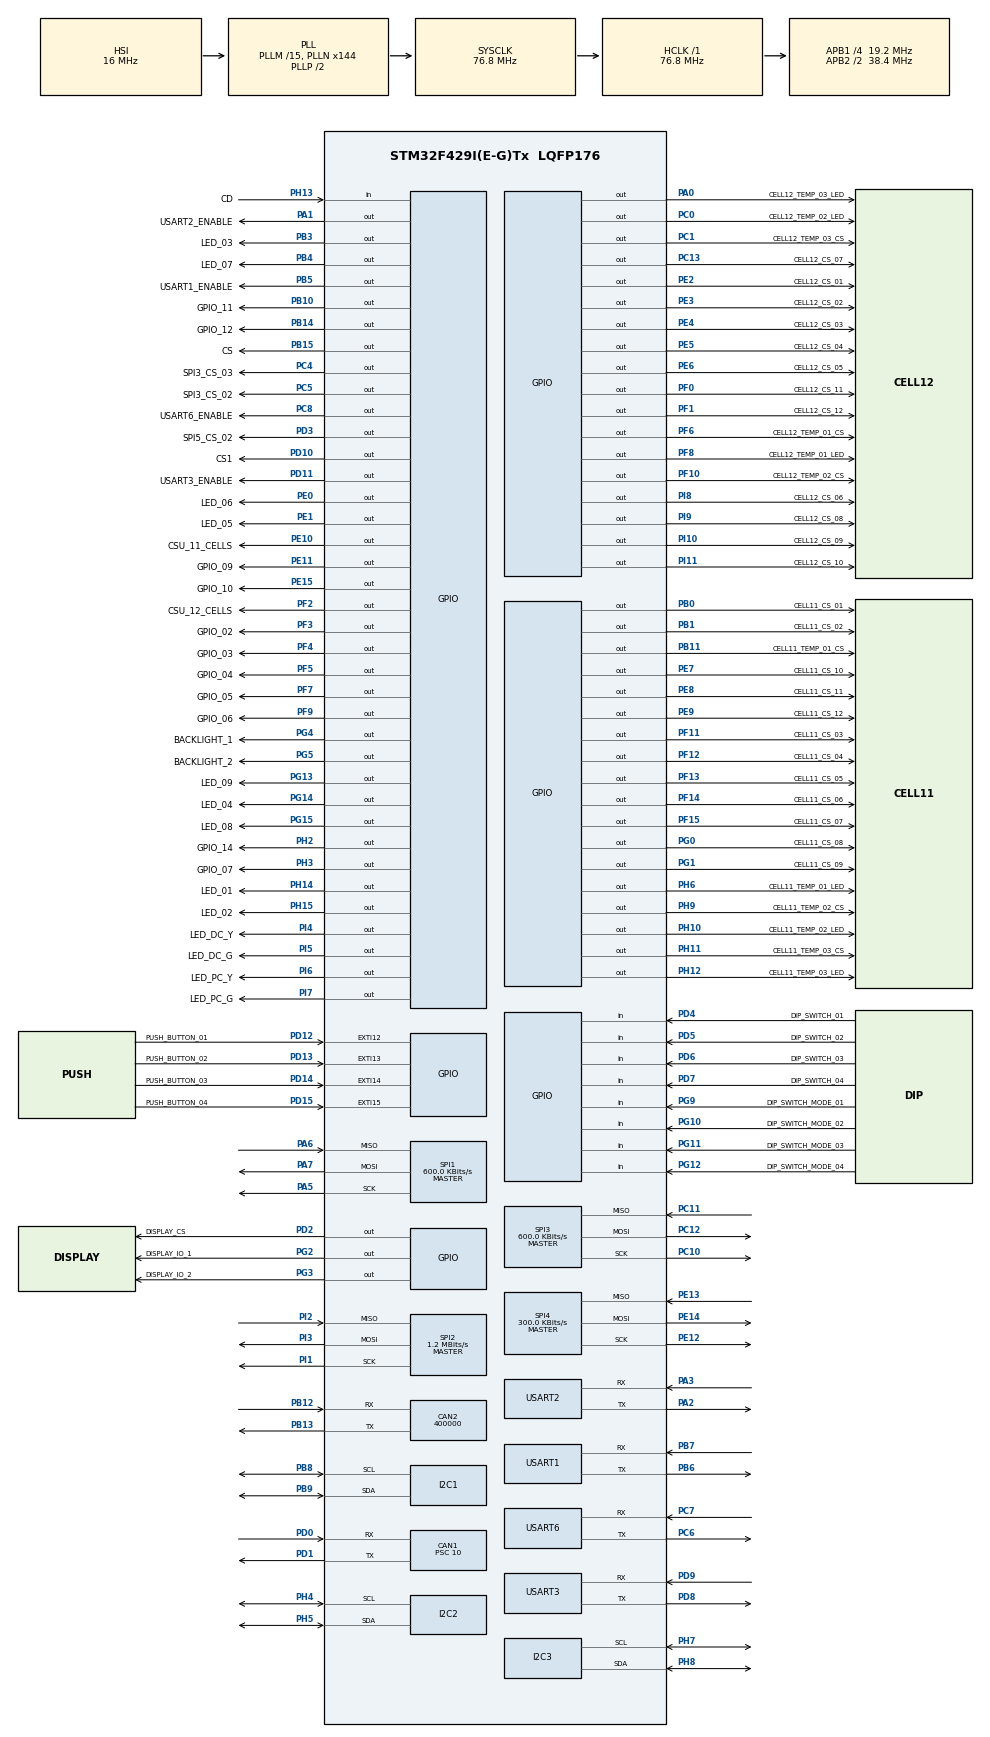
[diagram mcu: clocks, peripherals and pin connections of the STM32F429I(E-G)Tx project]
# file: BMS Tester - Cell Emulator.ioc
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CAN1.BS1=CAN_BS1_13TQ
CAN1.BS2=CAN_BS2_4TQ
CAN1.CalculateBaudRate=106666
CAN1.CalculateTimeBit=9375
CAN1.CalculateTimeQuantum=520.8333333333334
CAN1.Prescaler=10
CAN2.CalculateBaudRate=400000
CAN2.CalculateTimeBit=2500
CAN2.CalculateTimeQuantum=833.3333333333334
FATFS._MAX_SS=4096
I2C2.I2C_Mode=I2C_Fast
I2C3.I2C_Mode=I2C_Fast
Mcu.Family=STM32F4
Mcu.Name=STM32F429I(E-G)Tx
Mcu.Package=LQFP176
NVIC.CAN1_RX0_IRQn=true\:0\:0\:false\:false\:true\:true\:true\:true
NVIC.CAN1_RX1_IRQn=true\:0\:0\:false\:false\:true\:true\:true\:true
NVIC.EXTI15_10_IRQn=true\:0\:0\:false\:false\:true\:true\:true\:true
NVIC.PriorityGroup=NVIC_PRIORITYGROUP_4
NVIC.TIM1_UP_TIM10_IRQn=true\:0\:0\:false\:false\:true\:true\:true\:true
NVIC.USART1_IRQn=true\:0\:0\:false\:false\:true\:true\:true\:true
NVIC.USART2_IRQn=true\:0\:0\:false\:false\:true\:true\:true\:true
NVIC.USART3_IRQn=true\:0\:0\:false\:false\:true\:true\:true\:true
NVIC.USART6_IRQn=true\:0\:0\:false\:false\:true\:true\:true\:true
PA0/WKUP.GPIO_Label=CELL12_TEMP_03_LED
PA0/WKUP.GPIO_PuPd=GPIO_PULLDOWN
PA0/WKUP.GPIO_Speed=GPIO_SPEED_FREQ_VERY_HIGH
PA0/WKUP.PinState=GPIO_PIN_SET
PA0/WKUP.Signal=GPIO_Output
PA1.GPIO_Label=USART2_ENABLE
PA1.GPIO_Speed=GPIO_SPEED_FREQ_HIGH
PA1.PinState=GPIO_PIN_RESET
PA1.Signal=GPIO_Output
PA13.Mode=Serial_Wire
PA13.Signal=SYS_JTMS-SWDIO
PA14.Mode=Serial_Wire
PA14.Signal=SYS_JTCK-SWCLK
PA2.Mode=Asynchronous
PA2.Signal=USART2_TX
PA3.Mode=Asynchronous
PA3.Signal=USART2_RX
PA5.Mode=Full_Duplex_Master
PA5.Signal=SPI1_SCK
PA6.Mode=Full_Duplex_Master
PA6.Signal=SPI1_MISO
PA7.Mode=Full_Duplex_Master
PA7.Signal=SPI1_MOSI
PB0.GPIO_Label=CELL11_CS_01
PB0.PinState=GPIO_PIN_SET
PB0.Signal=GPIO_Output
PB1.GPIO_Label=CELL11_CS_02
PB1.PinState=GPIO_PIN_SET
PB1.Signal=GPIO_Output
PB10.GPIO_Label=GPIO_11
PB10.Signal=GPIO_Output
PB11.GPIO_Label=CELL11_TEMP_01_CS
PB11.GPIO_PuPd=GPIO_PULLUP
PB11.GPIO_Speed=GPIO_SPEED_FREQ_VERY_HIGH
PB11.PinState=GPIO_PIN_SET
PB11.Signal=GPIO_Output
PB12.Mode=CAN_Activate
PB12.Signal=CAN2_RX
PB13.Mode=CAN_Activate
PB13.Signal=CAN2_TX
PB14.GPIO_Label=GPIO_12
PB14.Signal=GPIO_Output
PB15.GPIO_Label=CS
PB15.PinState=GPIO_PIN_SET
PB15.Signal=GPIO_Output
PB3.GPIO_Label=LED_03
PB3.Signal=GPIO_Output
PB4.GPIO_Label=LED_07
PB4.Signal=GPIO_Output
PB5.GPIO_Label=USART1_ENABLE
PB5.Signal=GPIO_Output
PB6.Mode=Asynchronous
PB6.Signal=USART1_TX
PB7.Mode=Asynchronous
PB7.Signal=USART1_RX
PB8.Mode=I2C
PB8.Signal=I2C1_SCL
PB9.Mode=I2C
PB9.Signal=I2C1_SDA
PC0.GPIO_Label=CELL12_TEMP_02_LED
PC0.GPIO_PuPd=GPIO_PULLDOWN
PC0.GPIO_Speed=GPIO_SPEED_FREQ_VERY_HIGH
PC0.PinState=GPIO_PIN_SET
PC0.Signal=GPIO_Output
PC1.GPIO_Label=CELL12_TEMP_03_CS
PC1.GPIO_PuPd=GPIO_PULLUP
PC1.GPIO_Speed=GPIO_SPEED_FREQ_VERY_HIGH
PC1.PinState=GPIO_PIN_SET
PC1.Signal=GPIO_Output
PC10.Mode=Full_Duplex_Master
PC10.Signal=SPI3_SCK
PC11.Mode=Full_Duplex_Master
PC11.Signal=SPI3_MISO
PC12.Mode=Full_Duplex_Master
PC12.Signal=SPI3_MOSI
PC13.GPIO_Label=CELL12_CS_07
PC13.PinState=GPIO_PIN_SET
PC13.Signal=GPIO_Output
PC14/OSC32_IN.Mode=LSE-External-Oscillator
PC14/OSC32_IN.Signal=RCC_OSC32_IN
PC15/OSC32_OUT.Mode=LSE-External-Oscillator
PC15/OSC32_OUT.Signal=RCC_OSC32_OUT
PC4.GPIO_Label=SPI3_CS_03
PC4.PinState=GPIO_PIN_SET
PC4.Signal=GPIO_Output
PC5.GPIO_Label=SPI3_CS_02
PC5.PinState=GPIO_PIN_SET
PC5.Signal=GPIO_Output
PC6.Mode=Asynchronous
PC6.Signal=USART6_TX
PC7.Mode=Asynchronous
PC7.Signal=USART6_RX
PC8.GPIO_Label=USART6_ENABLE
PC8.Signal=GPIO_Output
PD0.Mode=CAN_Activate
PD0.Signal=CAN1_RX
PD1.Mode=CAN_Activate
PD1.Signal=CAN1_TX
PD10.GPIO_Label=CS1
PD10.PinState=GPIO_PIN_SET
PD10.Signal=GPIO_Output
PD11.GPIO_Label=USART3_ENABLE
PD11.Signal=GPIO_Output
PD12.GPIO_Label=PUSH_BUTTON_01
PD12.Signal=GPXTI12
PD13.GPIO_Label=PUSH_BUTTON_02
PD13.Signal=GPXTI13
PD14.GPIO_Label=PUSH_BUTTON_03
PD14.Signal=GPXTI14
PD15.GPIO_Label=PUSH_BUTTON_04
PD15.Signal=GPXTI15
PD2.GPIO_Label=DISPLAY_CS
PD2.Signal=GPIO_Output
PD3.GPIO_Label=SPI5_CS_02
PD3.Signal=GPIO_Output
PD4.GPIO_Label=DIP_SWITCH_01
PD4.Signal=GPIO_Input
PD5.GPIO_Label=DIP_SWITCH_02
PD5.Signal=GPIO_Input
PD6.GPIO_Label=DIP_SWITCH_03
PD6.Signal=GPIO_Input
PD7.GPIO_Label=DIP_SWITCH_04
PD7.Signal=GPIO_Input
PD8.Mode=Asynchronous
PD8.Signal=USART3_TX
PD9.Mode=Asynchronous
PD9.Signal=USART3_RX
PE0.GPIO_Label=LED_06
PE0.Signal=GPIO_Output
PE1.GPIO_Label=LED_05
PE1.Signal=GPIO_Output
PE10.GPIO_Label=CSU_11_CELLS
PE10.PinState=GPIO_PIN_SET
PE10.Signal=GPIO_Output
PE11.GPIO_Label=GPIO_09
PE11.Signal=GPIO_Output
PE12.Mode=Full_Duplex_Master
PE12.Signal=SPI4_SCK
PE13.GPIO_PuPd=GPIO_PULLUP
PE13.Mode=Full_Duplex_Master
PE13.Signal=SPI4_MISO
PE14.Mode=Full_Duplex_Master
PE14.Signal=SPI4_MOSI
PE15.GPIO_Label=GPIO_10
PE15.Signal=GPIO_Output
PE2.GPIO_Label=CELL12_CS_01
PE2.PinState=GPIO_PIN_SET
PE2.Signal=GPIO_Output
PE3.GPIO_Label=CELL12_CS_02
PE3.PinState=GPIO_PIN_SET
PE3.Signal=GPIO_Output
PE4.GPIO_Label=CELL12_CS_03
PE4.PinState=GPIO_PIN_SET
PE4.Signal=GPIO_Output
PE5.GPIO_Label=CELL12_CS_04
PE5.PinState=GPIO_PIN_SET
PE5.Signal=GPIO_Output
PE6.GPIO_Label=CELL12_CS_05
PE6.PinState=GPIO_PIN_SET
PE6.Signal=GPIO_Output
PE7.GPIO_Label=CELL11_CS_10
PE7.GPIO_PuPd=GPIO_NOPULL
PE7.PinState=GPIO_PIN_SET
PE7.Signal=GPIO_Output
PE8.GPIO_Label=CELL11_CS_11
PE8.PinState=GPIO_PIN_SET
PE8.Signal=GPIO_Output
PE9.GPIO_Label=CELL11_CS_12
PE9.PinState=GPIO_PIN_SET
PE9.Signal=GPIO_Output
PF0.GPIO_Label=CELL12_CS_11
PF0.PinState=GPIO_PIN_SET
PF0.Signal=GPIO_Output
PF1.GPIO_Label=CELL12_CS_12
PF1.PinState=GPIO_PIN_SET
PF1.Signal=GPIO_Output
PF10.GPIO_Label=CELL12_TEMP_02_CS
PF10.GPIO_PuPd=GPIO_PULLUP
PF10.GPIO_Speed=GPIO_SPEED_FREQ_VERY_HIGH
PF10.PinState=GPIO_PIN_SET
PF10.Signal=GPIO_Output
PF11.GPIO_Label=CELL11_CS_03
PF11.PinState=GPIO_PIN_SET
PF11.Signal=GPIO_Output
PF12.GPIO_Label=CELL11_CS_04
PF12.PinState=GPIO_PIN_SET
PF12.Signal=GPIO_Output
PF13.GPIO_Label=CELL11_CS_05
PF13.PinState=GPIO_PIN_SET
PF13.Signal=GPIO_Output
PF14.GPIO_Label=CELL11_CS_06
PF14.PinState=GPIO_PIN_SET
PF14.Signal=GPIO_Output
PF15.GPIO_Label=CELL11_CS_07
PF15.PinState=GPIO_PIN_SET
PF15.Signal=GPIO_Output
PF2.GPIO_Label=CSU_12_CELLS
PF2.GPIO_Speed=GPIO_SPEED_FREQ_HIGH
PF2.PinState=GPIO_PIN_SET
PF2.Signal=GPIO_Output
PF3.GPIO_Label=GPIO_02
PF3.Signal=GPIO_Output
PF4.GPIO_Label=GPIO_03
PF4.Signal=GPIO_Output
PF5.GPIO_Label=GPIO_04
PF5.Signal=GPIO_Output
PF6.GPIO_Label=CELL12_TEMP_01_CS
PF6.GPIO_PuPd=GPIO_PULLUP
PF6.GPIO_Speed=GPIO_SPEED_FREQ_VERY_HIGH
PF6.PinState=GPIO_PIN_SET
PF6.Signal=GPIO_Output
PF7.GPIO_Label=GPIO_05
PF7.Signal=GPIO_Output
PF8.GPIO_Label=CELL12_TEMP_01_LED
PF8.GPIO_PuPd=GPIO_PULLDOWN
PF8.GPIO_Speed=GPIO_SPEED_FREQ_VERY_HIGH
PF8.PinState=GPIO_PIN_SET
PF8.Signal=GPIO_Output
PF9.GPIO_Label=GPIO_06
PF9.Signal=GPIO_Output
PG0.GPIO_Label=CELL11_CS_08
PG0.PinState=GPIO_PIN_SET
PG0.Signal=GPIO_Output
PG1.GPIO_Label=CELL11_CS_09
PG1.GPIO_PuPd=GPIO_NOPULL
PG1.PinState=GPIO_PIN_SET
PG1.Signal=GPIO_Output
PG10.GPIO_Label=DIP_SWITCH_MODE_02
PG10.Signal=GPIO_Input
PG11.GPIO_Label=DIP_SWITCH_MODE_03
PG11.Signal=GPIO_Input
PG12.GPIO_Label=DIP_SWITCH_MODE_04
PG12.Signal=GPIO_Input
PG13.GPIO_Label=LED_09
PG13.Signal=GPIO_Output
PG14.GPIO_Label=LED_04
PG14.Signal=GPIO_Output
PG15.GPIO_Label=LED_08
PG15.Signal=GPIO_Output
PG2.GPIO_Label=DISPLAY_IO_1
PG2.Signal=GPIO_Output
PG3.GPIO_Label=DISPLAY_IO_2
PG3.Signal=GPIO_Output
PG4.GPIO_Label=BACKLIGHT_1
PG4.Signal=GPIO_Output
PG5.GPIO_Label=BACKLIGHT_2
PG5.Signal=GPIO_Output
PG9.GPIO_Label=DIP_SWITCH_MODE_01
PG9.Signal=GPIO_Input
PH0/OSC_IN.Mode=HSE-External-Oscillator
PH0/OSC_IN.Signal=RCC_OSC_IN
PH1/OSC_OUT.Mode=HSE-External-Oscillator
PH1/OSC_OUT.Signal=RCC_OSC_OUT
PH10.GPIO_Label=CELL11_TEMP_02_LED
PH10.GPIO_PuPd=GPIO_PULLDOWN
PH10.GPIO_Speed=GPIO_SPEED_FREQ_VERY_HIGH
PH10.PinState=GPIO_PIN_SET
PH10.Signal=GPIO_Output
PH11.GPIO_Label=CELL11_TEMP_03_CS
PH11.GPIO_PuPd=GPIO_PULLUP
PH11.GPIO_Speed=GPIO_SPEED_FREQ_VERY_HIGH
PH11.PinState=GPIO_PIN_SET
PH11.Signal=GPIO_Output
PH12.GPIO_Label=CELL11_TEMP_03_LED
PH12.GPIO_PuPd=GPIO_PULLDOWN
PH12.GPIO_Speed=GPIO_SPEED_FREQ_VERY_HIGH
PH12.PinState=GPIO_PIN_SET
PH12.Signal=GPIO_Output
PH13.GPIO_Label=CD
PH13.GPIO_PuPd=GPIO_PULLUP
PH13.Signal=GPIO_Input
PH14.GPIO_Label=LED_01
PH14.Signal=GPIO_Output
PH15.GPIO_Label=LED_02
PH15.Signal=GPIO_Output
PH2.GPIO_Label=GPIO_14
PH2.Signal=GPIO_Output
PH3.GPIO_Label=GPIO_07
PH3.Signal=GPIO_Output
PH4.Mode=I2C
PH4.Signal=I2C2_SCL
PH5.Mode=I2C
PH5.Signal=I2C2_SDA
PH6.GPIO_Label=CELL11_TEMP_01_LED
PH6.GPIO_PuPd=GPIO_PULLDOWN
PH6.GPIO_Speed=GPIO_SPEED_FREQ_VERY_HIGH
PH6.PinState=GPIO_PIN_SET
PH6.Signal=GPIO_Output
PH7.Mode=I2C
PH7.Signal=I2C3_SCL
PH8.Mode=I2C
PH8.Signal=I2C3_SDA
PH9.GPIO_Label=CELL11_TEMP_02_CS
PH9.GPIO_PuPd=GPIO_PULLUP
PH9.GPIO_Speed=GPIO_SPEED_FREQ_VERY_HIGH
PH9.PinState=GPIO_PIN_SET
PH9.Signal=GPIO_Output
PI1.Mode=Full_Duplex_Master
PI1.Signal=SPI2_SCK
PI10.GPIO_Label=CELL12_CS_09
PI10.PinState=GPIO_PIN_SET
PI10.Signal=GPIO_Output
PI11.GPIO_Label=CELL12_CS_10
PI11.PinState=GPIO_PIN_SET
PI11.Signal=GPIO_Output
PI2.Mode=Full_Duplex_Master
PI2.Signal=SPI2_MISO
PI3.Mode=Full_Duplex_Master
PI3.Signal=SPI2_MOSI
PI4.GPIO_Label=LED_DC_Y
PI4.Signal=GPIO_Output
PI5.GPIO_Label=LED_DC_G
PI5.Signal=GPIO_Output
PI6.GPIO_Label=LED_PC_Y
PI6.Signal=GPIO_Output
PI7.GPIO_Label=LED_PC_G
PI7.Signal=GPIO_Output
PI8.GPIO_Label=CELL12_CS_06
PI8.PinState=GPIO_PIN_SET
PI8.Signal=GPIO_Output
PI9.GPIO_Label=CELL12_CS_08
PI9.PinState=GPIO_PIN_SET
PI9.Signal=GPIO_Output
ProjectManager.HeapSize=0x200
ProjectManager.StackSize=0x400
ProjectManager.TargetToolchain=STM32CubeIDE
RCC.48MHZClocksFreq_Value=30720000
RCC.AHBFreq_Value=76800000
RCC.APB1CLKDivider=RCC_HCLK_DIV4
RCC.APB1Freq_Value=19200000
RCC.APB1TimFreq_Value=38400000
RCC.APB2CLKDivider=RCC_HCLK_DIV2
RCC.APB2Freq_Value=38400000
RCC.APB2TimFreq_Value=76800000
RCC.CortexFreq_Value=76800000
RCC.HCLKFreq_Value=76800000
RCC.HSE_VALUE=25000000
RCC.HSI_VALUE=16000000
RCC.PLLM=15
RCC.PLLN=144
RCC.PLLQ=5
RCC.SYSCLKFreq_VALUE=76800000
RCC.SYSCLKSource=RCC_SYSCLKSOURCE_PLLCLK
RCC.VCOOutputFreq_Value=153600000
SPI1.BaudRatePrescaler=SPI_BAUDRATEPRESCALER_64
SPI1.CLKPhase=SPI_PHASE_2EDGE
SPI1.CRCCalculation=SPI_CRCCALCULATION_DISABLE
SPI1.CalculateBaudRate=600.0 KBits/s
SPI1.Direction=SPI_DIRECTION_2LINES
SPI1.Mode=SPI_MODE_MASTER
SPI1.VirtualType=VM_MASTER
SPI2.BaudRatePrescaler=SPI_BAUDRATEPRESCALER_16
SPI2.CLKPhase=SPI_PHASE_2EDGE
SPI2.CalculateBaudRate=1.2 MBits/s
SPI2.Direction=SPI_DIRECTION_2LINES
SPI2.Mode=SPI_MODE_MASTER
SPI2.VirtualType=VM_MASTER
SPI3.BaudRatePrescaler=SPI_BAUDRATEPRESCALER_32
SPI3.CalculateBaudRate=600.0 KBits/s
SPI3.Direction=SPI_DIRECTION_2LINES
SPI3.Mode=SPI_MODE_MASTER
SPI3.VirtualType=VM_MASTER
SPI4.BaudRatePrescaler=SPI_BAUDRATEPRESCALER_128
SPI4.CalculateBaudRate=300.0 KBits/s
SPI4.Direction=SPI_DIRECTION_2LINES
SPI4.Mode=SPI_MODE_MASTER
SPI4.VirtualType=VM_MASTER
TIM1.Period=999
TIM1.Prescaler=999
USART1.VirtualMode=VM_ASYNC
USART2.VirtualMode=VM_ASYNC
USART3.VirtualMode=VM_ASYNC
USART6.VirtualMode=VM_ASYNC
VP_FATFS_VS_Generic.Mode=User_defined
VP_TIM1_VS_ClockSourceINT.Mode=Internal
board=custom

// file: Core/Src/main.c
/* USER CODE BEGIN Header */
/**
  ******************************************************************************
  * @file           : main.c
  * @brief          : Main program body
  ******************************************************************************
  * @attention
  *
  * Copyright (c) 2025 STMicroelectronics.
  * All rights reserved.
  *
  * This software is licensed under terms that can be found in the LICENSE file
  * in the root directory of this software component.
  * If no LICENSE file comes with this software, it is provided AS-IS.
  *
  ******************************************************************************
  */
/* USER CODE END Header */
#include "main.h"
#include "fatfs.h"

/* USER CODE BEGIN Includes */

#include "main_data.h"

#include "display.h"

#include "Temp_controller.h"

#include "INA229.h"
#include  "config.h"
#include "mcu.h"
#include <math.h>

#include "flash_LTC.h"
#include "LTC6811.h"
#include "LTC681x.h"
#include "LTC68xx_API.h"
#include <stdlib.h>

#include "gpio_expander.h"
#include "rtc.h"
#include "button_led.h"

#include "BMS_test_protocol.h"

#include "modbusSlave.h"

/* USER CODE END Includes */

/* USER CODE BEGIN PD */
int resistance[6] = {10, 10, 10, 10, 10, 10};

//uint8_t DC_chain = 0 ;

float set_temp = 1000.0 ;

uint8_t modebus_rx_flag = 0 ;
uint8_t flag_1 = 0 ;
uint8_t flag_2 = 0 ;
uint8_t flag_3 = 0 ;
uint8_t timeout_flag;
uint8_t testcount;

uint8_t RxData_modbus_01[256];
uint8_t TxData_modbus_01[256];

uint8_t RxData_modbus_02[256];
uint8_t TxData_modbus_02[256];

uint8_t RxData_modbus_03[256];
uint8_t TxData_modbus_03[256];

uint8_t RxData_modbus_04[256];
uint8_t TxData_modbus_04[256];

uint8_t address;
HAL_StatusTypeDef result;

int count =0 ;

#define STARTUP_TEMP_C 25.0f  // Desired startup temperature in °C

#define UI_BUFFER_SIZE 32
#define CRC16_CCITT 0x1021
#define debug
#define BAUD    115200
#define T_char  750
#define T_frame 1750

INA229_Handle ina229_devices[NUM_INA229];

/* USER CODE END PD */

CAN_HandleTypeDef hcan1;
CAN_HandleTypeDef hcan2;

I2C_HandleTypeDef hi2c1;
I2C_HandleTypeDef hi2c2;
I2C_HandleTypeDef hi2c3;

SPI_HandleTypeDef hspi1;
SPI_HandleTypeDef hspi2;
SPI_HandleTypeDef hspi3;
SPI_HandleTypeDef hspi4;

TIM_HandleTypeDef htim1;

UART_HandleTypeDef huart1;
UART_HandleTypeDef huart2;
UART_HandleTypeDef huart3;
UART_HandleTypeDef huart6;

void SystemClock_Config(void);
static void MX_GPIO_Init(void);
static void MX_SPI1_Init(void);
static void MX_SPI2_Init(void);
static void MX_I2C2_Init(void);
static void MX_I2C3_Init(void);
static void MX_SPI3_Init(void);
static void MX_SPI4_Init(void);
static void MX_CAN1_Init(void);
static void MX_CAN2_Init(void);
static void MX_I2C1_Init(void);
static void MX_USART1_UART_Init(void);
static void MX_USART2_UART_Init(void);
static void MX_USART3_UART_Init(void);
static void MX_USART6_UART_Init(void);
static void MX_TIM1_Init(void);
/* USER CODE BEGIN PFP */

//void Scan_I2C_Bus(void);

//// Define configuration structure using constant values
//typedef struct {
//    uint8_t cell_id;      // Cell ID as a number instead of enum
//    uint8_t ina_index;    // Index of INA229 (0-23)
//    GPIO_TypeDef* gpio;   // GPIO port (this is actually a constant address)
//    uint16_t cs_pin;      // Chip select pin
//    uint16_t led_pin;     // LED pin
//} Cell_Config;

// Function declarations

void Voltage_Sequence_Automatic(void);

void Set_voltage_and_measure(const Cell_Config* cell, float voltage);

void init_ina229_devices(void) ;

void HAL_UARTEx_RxEventCallback(UART_HandleTypeDef *huart, uint16_t Size);

void test_currecnt_senser();

/* USER CODE END PFP */

int main(void)
{

  /* USER CODE BEGIN 1 */
	timeout_flag = 0;
    memset(RxData_modbus_01, 0, sizeof(RxData_modbus_01));
    memset(TxData_modbus_01, 0, sizeof(TxData_modbus_01));

  /* USER CODE END 1 */

  /* MCU Configuration--------------------------------------------------------*/

  /* Reset of all peripherals, Initializes the Flash interface and the Systick. */
  HAL_Init();

  /* Configure the system clock */
  SystemClock_Config();

  /* Initialize all configured peripherals */
  MX_GPIO_Init();
  MX_SPI1_Init();
  MX_SPI2_Init();
  MX_I2C2_Init();
  MX_I2C3_Init();
  MX_SPI3_Init();
  MX_SPI4_Init();
  MX_CAN1_Init();
  MX_CAN2_Init();
  MX_I2C1_Init();
  MX_USART1_UART_Init();
  MX_USART2_UART_Init();
  MX_USART3_UART_Init();
  MX_USART6_UART_Init();
  MX_FATFS_Init();
  MX_TIM1_Init();
  /* USER CODE BEGIN 2 */

  RTC_Init();
  LED_Init();		/* Reset all LEDs */

  init_ina229_devices();

  for (int i = 0; i < NUM_INA229; i++)
  { INA229_config(ina229_devices[i]); HAL_Delay(10); }

  mcu_spiInit(0);
  HAL_Delay(10);

//

  //init ltc ics

  //--------------------------------------------------------------//

	LTC6811_init_cfg(TOTAL_IC, BMS_IC);
	uint8_t main_current_ic;
	for (main_current_ic = 0; main_current_ic < TOTAL_IC; main_current_ic++) {
		LTC6811_set_cfgr(main_current_ic, BMS_IC, REF_ON, ADCOPT, GPIOBITS_A,
				DCCBITS_A, DCTOBITS, UV, OV);
	}
	LTC6811_wrcfg(TOTAL_IC, BMS_IC);
	LTC6811_reset_crc_count(TOTAL_IC, BMS_IC);
	LTC6811_init_reg_limits(TOTAL_IC, BMS_IC);

  //--------------------------------------------------------------//

  /* Initialize the display module */
  Display_Init();

  /* Display the main title page */
  Display_MainTitlePage();

  /* Initialize the expander at address 0x20 by configuring all its pins as outputs */
  Expander_InitAllDevices(&hi2c2);
  Expander_InitAllDevices(&hi2c3);

	HAL_UARTEx_ReceiveToIdle_IT(&huart1, RxData_modbus_01, 256);

	HAL_UARTEx_ReceiveToIdle_IT(&huart2, RxData_modbus_02, 256);

	HAL_UARTEx_ReceiveToIdle_IT(&huart3, RxData_modbus_03, 256);

	HAL_UARTEx_ReceiveToIdle_IT(&huart6, RxData_modbus_04, 256);

	HAL_TIM_Base_Start_IT(&htim1);

	float startup_resistance = ntc_resistance(STARTUP_TEMP_C);

//fixing the startup resistance of temperature cards
#ifdef start_Resistance_fix
		  cell12_Temp_01_startup(startup_resistance);
		  cell12_Temp_02_startup(startup_resistance);
		  cell12_Temp_03_startup(startup_resistance);
		  cell11_Temp_01_startup(startup_resistance);
		  cell11_Temp_02_startup(startup_resistance);
		  cell11_Temp_03_startup(startup_resistance);

#endif

  /* USER CODE END 2 */

  /* Infinite loop */
  /* USER CODE BEGIN WHILE */
  while (1)
  {
//	  RTC_ReadTime();
//	  char timeStr[16];
//	  char dateStr[16];
//	  sprintf(timeStr, "%02d:%02d:%02d", time.hour, time.minute, time.second);
//	  sprintf(dateStr, "%02d/%02d/%02d", time.day, time.month, time.year);
//	  display_lcd(timeStr);
//	  HAL_Delay(100);
//	  LED_Set(7, 0);

    /* USER CODE END WHILE */

    /* USER CODE BEGIN 3 */

	  Display_HandleButtons();
	  Display_Update();

	  HAL_Delay(10);
	  tester_setup();

	  if (timeout_flag )

	  {
//		  memset(Rx_Data, 0, sizeof(Rx_Data));

//		  sprintf(Tx_Data, "F103 %d", indx++);
//		    send_Data (Tx_Data);
		    HAL_Delay(10);
//	        tester_setup();

	    	memset(RxData_modbus_01, 0, sizeof(RxData_modbus_01));
	    	memset(TxData_modbus_01, 0, sizeof(TxData_modbus_01));
		  modebus_rx_flag = 0 ;

		    flag_1 = 0 ;

			  HAL_TIM_Base_Stop_IT(&htim1);
			  timeout_flag = 0;

//		  HAL_TIM_Base_Stop_IT(&htim1);

	  }

//		  cell12_Temp_01_Set(resistance[0]);
//		  cell12_Temp_02_Set(resistance[1]);
//		  cell12_Temp_03_Set(resistance[2]);
//		  cell11_Temp_01_Set(resistance[3]);
//		  cell11_Temp_02_Set(resistance[4]);
//		  cell11_Temp_03_Set(resistance[5]);

//	  cell12_Temp_01_Set(set_temp);
//	  cell12_Temp_02_Set(set_temp);
//	  cell12_Temp_03_Set(set_temp);
//
//		  cell11_Temp_01_Set(set_temp);
//		  cell11_Temp_02_Set(set_temp);
//		  cell11_Temp_03_Set(set_temp);

	  ////////////////////////////////////////////////////////////

	        // Perform voltage sequence and measurements

//		  Set_Output_Voltage(CELL_1, 4.2f);
//
//		  HAL_Delay(1000);
//
//		  Set_Output_Voltage(CELL_1, 2.0f);
//
//		  HAL_Delay(1000);
//
//		  Set_Output_Voltage(CELL_15, 4.2f);
//
//		  HAL_Delay(1000);
//
//
//		  Set_Output_Voltage(CELL_15, 2.0f);
//
//		  HAL_Delay(1000);
//
//		  Set_Output_Voltage(CELL_24, 4.2f);
//
//		  HAL_Delay(1000);
//
//		  Set_Output_Voltage(CELL_24, 2.0f);

//	        Voltage_Sequence_Automatic();

//      	cell_voltage_read();

//      	temparature_data_read();

//	        tester_setup();

	        // Process battery tests
//	        for (int cell = CELL_1; cell <= CELL_24; cell++) {
//	        	Set_LED_status(cell, ON);
//	        }

//	        test_currecnt_senser();

//	        for (int cell = CELL_1; cell <= CELL_24; cell++) {
//	        	Set_LED_status(cell, OFF);
//	        }
//	        HAL_Delay(1000);
//
//	        for (int cell = CELL_1; cell <= CELL_24; cell++) {
//	        	Set_Output_Voltage(cell, 4.2);
//	        }
//
//
//	        HAL_Delay(1000);
//
//	        for (int cell = CELL_1; cell <= CELL_24; cell++) {
//	        	Set_Output_Voltage(cell, 2.0);
//	        }
//	        HAL_Delay(1000);
//
//	        for (int cell = CELL_1; cell <= CELL_24; cell++) {
//	        	Set_LED_status(cell, ON);
//	        }

//
//HAL_GPIO_WritePin(GPIOC, SPI3_CS_03_Pin|SPI3_CS_02_Pin, GPIO_PIN_RESET);
//
//
//cell_voltage_read();
//delay_time_us(500000);
//temparature_data_read();
//
//HAL_GPIO_WritePin(GPIOC, SPI3_CS_03_Pin|SPI3_CS_02_Pin, GPIO_PIN_SET);
//
//HAL_Delay(10);
//
//
//cell_voltage_read();
//delay_time_us(500000);
//temparature_data_read();

//delay_time_us(500000);
//--------------------------------------------------------------//

		  	/////////////////////////////////////////////////////////////
//Scan_I2C_Bus();

  }
  /* USER CODE END 3 */
}

void SystemClock_Config(void)
{
  RCC_OscInitTypeDef RCC_OscInitStruct = {0};
  RCC_ClkInitTypeDef RCC_ClkInitStruct = {0};

  /** Configure the main internal regulator output voltage
  */
  __HAL_RCC_PWR_CLK_ENABLE();
  __HAL_PWR_VOLTAGESCALING_CONFIG(PWR_REGULATOR_VOLTAGE_SCALE3);

  /** Initializes the RCC Oscillators according to the specified parameters
  * in the RCC_OscInitTypeDef structure.
  */
  RCC_OscInitStruct.OscillatorType = RCC_OSCILLATORTYPE_HSI;
  RCC_OscInitStruct.HSIState = RCC_HSI_ON;
  RCC_OscInitStruct.HSICalibrationValue = RCC_HSICALIBRATION_DEFAULT;
  RCC_OscInitStruct.PLL.PLLState = RCC_PLL_ON;
  RCC_OscInitStruct.PLL.PLLSource = RCC_PLLSOURCE_HSI;
  RCC_OscInitStruct.PLL.PLLM = 15;
  RCC_OscInitStruct.PLL.PLLN = 144;
  RCC_OscInitStruct.PLL.PLLP = RCC_PLLP_DIV2;
  RCC_OscInitStruct.PLL.PLLQ = 5;
  if (HAL_RCC_OscConfig(&RCC_OscInitStruct) != HAL_OK)
  {
    Error_Handler();
  }

  /** Initializes the CPU, AHB and APB buses clocks
  */
  RCC_ClkInitStruct.ClockType = RCC_CLOCKTYPE_HCLK|RCC_CLOCKTYPE_SYSCLK
                              |RCC_CLOCKTYPE_PCLK1|RCC_CLOCKTYPE_PCLK2;
  RCC_ClkInitStruct.SYSCLKSource = RCC_SYSCLKSOURCE_PLLCLK;
  RCC_ClkInitStruct.AHBCLKDivider = RCC_SYSCLK_DIV1;
  RCC_ClkInitStruct.APB1CLKDivider = RCC_HCLK_DIV4;
  RCC_ClkInitStruct.APB2CLKDivider = RCC_HCLK_DIV2;

  if (HAL_RCC_ClockConfig(&RCC_ClkInitStruct, FLASH_LATENCY_2) != HAL_OK)
  {
    Error_Handler();
  }
}

static void MX_CAN1_Init(void)
{

  hcan1.Instance = CAN1;
  hcan1.Init.Prescaler = 10;
  hcan1.Init.Mode = CAN_MODE_NORMAL;
  hcan1.Init.SyncJumpWidth = CAN_SJW_1TQ;
  hcan1.Init.TimeSeg1 = CAN_BS1_13TQ;
  hcan1.Init.TimeSeg2 = CAN_BS2_4TQ;
  hcan1.Init.TimeTriggeredMode = DISABLE;
  hcan1.Init.AutoBusOff = DISABLE;
  hcan1.Init.AutoWakeUp = DISABLE;
  hcan1.Init.AutoRetransmission = DISABLE;
  hcan1.Init.ReceiveFifoLocked = DISABLE;
  hcan1.Init.TransmitFifoPriority = DISABLE;
  if (HAL_CAN_Init(&hcan1) != HAL_OK)
  {
    Error_Handler();
  }

}

static void MX_CAN2_Init(void)
{

  hcan2.Instance = CAN2;
  hcan2.Init.Prescaler = 16;
  hcan2.Init.Mode = CAN_MODE_NORMAL;
  hcan2.Init.SyncJumpWidth = CAN_SJW_1TQ;
  hcan2.Init.TimeSeg1 = CAN_BS1_1TQ;
  hcan2.Init.TimeSeg2 = CAN_BS2_1TQ;
  hcan2.Init.TimeTriggeredMode = DISABLE;
  hcan2.Init.AutoBusOff = DISABLE;
  hcan2.Init.AutoWakeUp = DISABLE;
  hcan2.Init.AutoRetransmission = DISABLE;
  hcan2.Init.ReceiveFifoLocked = DISABLE;
  hcan2.Init.TransmitFifoPriority = DISABLE;
  if (HAL_CAN_Init(&hcan2) != HAL_OK)
  {
    Error_Handler();
  }

}

static void MX_I2C1_Init(void)
{

  hi2c1.Instance = I2C1;
  hi2c1.Init.ClockSpeed = 100000;
  hi2c1.Init.DutyCycle = I2C_DUTYCYCLE_2;
  hi2c1.Init.OwnAddress1 = 0;
  hi2c1.Init.AddressingMode = I2C_ADDRESSINGMODE_7BIT;
  hi2c1.Init.DualAddressMode = I2C_DUALADDRESS_DISABLE;
  hi2c1.Init.OwnAddress2 = 0;
  hi2c1.Init.GeneralCallMode = I2C_GENERALCALL_DISABLE;
  hi2c1.Init.NoStretchMode = I2C_NOSTRETCH_DISABLE;
  if (HAL_I2C_Init(&hi2c1) != HAL_OK)
  {
    Error_Handler();
  }

  /** Configure Analogue filter
  */
  if (HAL_I2CEx_ConfigAnalogFilter(&hi2c1, I2C_ANALOGFILTER_ENABLE) != HAL_OK)
  {
    Error_Handler();
  }

  /** Configure Digital filter
  */
  if (HAL_I2CEx_ConfigDigitalFilter(&hi2c1, 0) != HAL_OK)
  {
    Error_Handler();
  }

}

static void MX_I2C2_Init(void)
{

  hi2c2.Instance = I2C2;
  hi2c2.Init.ClockSpeed = 400000;
  hi2c2.Init.DutyCycle = I2C_DUTYCYCLE_2;
  hi2c2.Init.OwnAddress1 = 0;
  hi2c2.Init.AddressingMode = I2C_ADDRESSINGMODE_7BIT;
  hi2c2.Init.DualAddressMode = I2C_DUALADDRESS_DISABLE;
  hi2c2.Init.OwnAddress2 = 0;
  hi2c2.Init.GeneralCallMode = I2C_GENERALCALL_DISABLE;
  hi2c2.Init.NoStretchMode = I2C_NOSTRETCH_DISABLE;
  if (HAL_I2C_Init(&hi2c2) != HAL_OK)
  {
    Error_Handler();
  }

  /** Configure Analogue filter
  */
  if (HAL_I2CEx_ConfigAnalogFilter(&hi2c2, I2C_ANALOGFILTER_ENABLE) != HAL_OK)
  {
    Error_Handler();
  }

  /** Configure Digital filter
  */
  if (HAL_I2CEx_ConfigDigitalFilter(&hi2c2, 0) != HAL_OK)
  {
    Error_Handler();
  }

}

static void MX_I2C3_Init(void)
{

  hi2c3.Instance = I2C3;
  hi2c3.Init.ClockSpeed = 400000;
  hi2c3.Init.DutyCycle = I2C_DUTYCYCLE_2;
  hi2c3.Init.OwnAddress1 = 0;
  hi2c3.Init.AddressingMode = I2C_ADDRESSINGMODE_7BIT;
  hi2c3.Init.DualAddressMode = I2C_DUALADDRESS_DISABLE;
  hi2c3.Init.OwnAddress2 = 0;
  hi2c3.Init.GeneralCallMode = I2C_GENERALCALL_DISABLE;
  hi2c3.Init.NoStretchMode = I2C_NOSTRETCH_DISABLE;
  if (HAL_I2C_Init(&hi2c3) != HAL_OK)
  {
    Error_Handler();
  }

  /** Configure Analogue filter
  */
  if (HAL_I2CEx_ConfigAnalogFilter(&hi2c3, I2C_ANALOGFILTER_ENABLE) != HAL_OK)
  {
    Error_Handler();
  }

  /** Configure Digital filter
  */
  if (HAL_I2CEx_ConfigDigitalFilter(&hi2c3, 0) != HAL_OK)
  {
    Error_Handler();
  }

}

static void MX_SPI1_Init(void)
{

  /* SPI1 parameter configuration*/
  hspi1.Instance = SPI1;
  hspi1.Init.Mode = SPI_MODE_MASTER;
  hspi1.Init.Direction = SPI_DIRECTION_2LINES;
  hspi1.Init.DataSize = SPI_DATASIZE_8BIT;
  hspi1.Init.CLKPolarity = SPI_POLARITY_LOW;
  hspi1.Init.CLKPhase = SPI_PHASE_2EDGE;
  hspi1.Init.NSS = SPI_NSS_SOFT;
  hspi1.Init.BaudRatePrescaler = SPI_BAUDRATEPRESCALER_64;
  hspi1.Init.FirstBit = SPI_FIRSTBIT_MSB;
  hspi1.Init.TIMode = SPI_TIMODE_DISABLE;
  hspi1.Init.CRCCalculation = SPI_CRCCALCULATION_DISABLE;
  hspi1.Init.CRCPolynomial = 10;
  if (HAL_SPI_Init(&hspi1) != HAL_OK)
  {
    Error_Handler();
  }

}

static void MX_SPI2_Init(void)
{

  /* SPI2 parameter configuration*/
  hspi2.Instance = SPI2;
  hspi2.Init.Mode = SPI_MODE_MASTER;
  hspi2.Init.Direction = SPI_DIRECTION_2LINES;
  hspi2.Init.DataSize = SPI_DATASIZE_8BIT;
  hspi2.Init.CLKPolarity = SPI_POLARITY_LOW;
  hspi2.Init.CLKPhase = SPI_PHASE_2EDGE;
  hspi2.Init.NSS = SPI_NSS_SOFT;
  hspi2.Init.BaudRatePrescaler = SPI_BAUDRATEPRESCALER_16;
  hspi2.Init.FirstBit = SPI_FIRSTBIT_MSB;
  hspi2.Init.TIMode = SPI_TIMODE_DISABLE;
  hspi2.Init.CRCCalculation = SPI_CRCCALCULATION_DISABLE;
  hspi2.Init.CRCPolynomial = 10;
  if (HAL_SPI_Init(&hspi2) != HAL_OK)
  {
    Error_Handler();
  }

}

static void MX_SPI3_Init(void)
{

  /* SPI3 parameter configuration*/
  hspi3.Instance = SPI3;
  hspi3.Init.Mode = SPI_MODE_MASTER;
  hspi3.Init.Direction = SPI_DIRECTION_2LINES;
  hspi3.Init.DataSize = SPI_DATASIZE_8BIT;
  hspi3.Init.CLKPolarity = SPI_POLARITY_LOW;
  hspi3.Init.CLKPhase = SPI_PHASE_1EDGE;
  hspi3.Init.NSS = SPI_NSS_SOFT;
  hspi3.Init.BaudRatePrescaler = SPI_BAUDRATEPRESCALER_32;
  hspi3.Init.FirstBit = SPI_FIRSTBIT_MSB;
  hspi3.Init.TIMode = SPI_TIMODE_DISABLE;
  hspi3.Init.CRCCalculation = SPI_CRCCALCULATION_DISABLE;
  hspi3.Init.CRCPolynomial = 10;
  if (HAL_SPI_Init(&hspi3) != HAL_OK)
  {
    Error_Handler();
  }

}

static void MX_SPI4_Init(void)
{

  /* SPI4 parameter configuration*/
  hspi4.Instance = SPI4;
  hspi4.Init.Mode = SPI_MODE_MASTER;
  hspi4.Init.Direction = SPI_DIRECTION_2LINES;
  hspi4.Init.DataSize = SPI_DATASIZE_8BIT;
  hspi4.Init.CLKPolarity = SPI_POLARITY_LOW;
  hspi4.Init.CLKPhase = SPI_PHASE_1EDGE;
  hspi4.Init.NSS = SPI_NSS_SOFT;
  hspi4.Init.BaudRatePrescaler = SPI_BAUDRATEPRESCALER_128;
  hspi4.Init.FirstBit = SPI_FIRSTBIT_MSB;
  hspi4.Init.TIMode = SPI_TIMODE_DISABLE;
  hspi4.Init.CRCCalculation = SPI_CRCCALCULATION_DISABLE;
  hspi4.Init.CRCPolynomial = 10;
  if (HAL_SPI_Init(&hspi4) != HAL_OK)
  {
    Error_Handler();
  }

}

static void MX_TIM1_Init(void)
{

  TIM_ClockConfigTypeDef sClockSourceConfig = {0};
  TIM_MasterConfigTypeDef sMasterConfig = {0};

  htim1.Instance = TIM1;
  htim1.Init.Prescaler = 999;
  htim1.Init.CounterMode = TIM_COUNTERMODE_UP;
  htim1.Init.Period = 999;
  htim1.Init.ClockDivision = TIM_CLOCKDIVISION_DIV1;
  htim1.Init.RepetitionCounter = 0;
  htim1.Init.AutoReloadPreload = TIM_AUTORELOAD_PRELOAD_DISABLE;
  if (HAL_TIM_Base_Init(&htim1) != HAL_OK)
  {
    Error_Handler();
  }
  sClockSourceConfig.ClockSource = TIM_CLOCKSOURCE_INTERNAL;
  if (HAL_TIM_ConfigClockSource(&htim1, &sClockSourceConfig) != HAL_OK)
  {
    Error_Handler();
  }
  sMasterConfig.MasterOutputTrigger = TIM_TRGO_RESET;
  sMasterConfig.MasterSlaveMode = TIM_MASTERSLAVEMODE_DISABLE;
  if (HAL_TIMEx_MasterConfigSynchronization(&htim1, &sMasterConfig) != HAL_OK)
  {
    Error_Handler();
  }

}

static void MX_USART1_UART_Init(void)
{

  huart1.Instance = USART1;
  huart1.Init.BaudRate = 115200;
  huart1.Init.WordLength = UART_WORDLENGTH_8B;
  huart1.Init.StopBits = UART_STOPBITS_1;
  huart1.Init.Parity = UART_PARITY_NONE;
  huart1.Init.Mode = UART_MODE_TX_RX;
  huart1.Init.HwFlowCtl = UART_HWCONTROL_NONE;
  huart1.Init.OverSampling = UART_OVERSAMPLING_16;
  if (HAL_UART_Init(&huart1) != HAL_OK)
  {
    Error_Handler();
  }

}

static void MX_USART2_UART_Init(void)
{

  huart2.Instance = USART2;
  huart2.Init.BaudRate = 115200;
  huart2.Init.WordLength = UART_WORDLENGTH_8B;
  huart2.Init.StopBits = UART_STOPBITS_1;
  huart2.Init.Parity = UART_PARITY_NONE;
  huart2.Init.Mode = UART_MODE_TX_RX;
  huart2.Init.HwFlowCtl = UART_HWCONTROL_NONE;
  huart2.Init.OverSampling = UART_OVERSAMPLING_16;
  if (HAL_UART_Init(&huart2) != HAL_OK)
  {
    Error_Handler();
  }

}

static void MX_USART3_UART_Init(void)
{

  huart3.Instance = USART3;
  huart3.Init.BaudRate = 115200;
  huart3.Init.WordLength = UART_WORDLENGTH_8B;
  huart3.Init.StopBits = UART_STOPBITS_1;
  huart3.Init.Parity = UART_PARITY_NONE;
  huart3.Init.Mode = UART_MODE_TX_RX;
  huart3.Init.HwFlowCtl = UART_HWCONTROL_NONE;
  huart3.Init.OverSampling = UART_OVERSAMPLING_16;
  if (HAL_UART_Init(&huart3) != HAL_OK)
  {
    Error_Handler();
  }

}

static void MX_USART6_UART_Init(void)
{

  huart6.Instance = USART6;
  huart6.Init.BaudRate = 115200;
  huart6.Init.WordLength = UART_WORDLENGTH_8B;
  huart6.Init.StopBits = UART_STOPBITS_1;
  huart6.Init.Parity = UART_PARITY_NONE;
  huart6.Init.Mode = UART_MODE_TX_RX;
  huart6.Init.HwFlowCtl = UART_HWCONTROL_NONE;
  huart6.Init.OverSampling = UART_OVERSAMPLING_16;
  if (HAL_UART_Init(&huart6) != HAL_OK)
  {
    Error_Handler();
  }

}

static void MX_GPIO_Init(void)
{
  GPIO_InitTypeDef GPIO_InitStruct = {0};

  /* GPIO Ports Clock Enable */
  __HAL_RCC_GPIOE_CLK_ENABLE();
  __HAL_RCC_GPIOI_CLK_ENABLE();
  __HAL_RCC_GPIOC_CLK_ENABLE();
  __HAL_RCC_GPIOF_CLK_ENABLE();
  __HAL_RCC_GPIOH_CLK_ENABLE();
  __HAL_RCC_GPIOA_CLK_ENABLE();
  __HAL_RCC_GPIOB_CLK_ENABLE();
  __HAL_RCC_GPIOG_CLK_ENABLE();
  __HAL_RCC_GPIOD_CLK_ENABLE();

  /*Configure GPIO pin Output Level */
  HAL_GPIO_WritePin(GPIOE, CELL12_CS_01_Pin|CELL12_CS_02_Pin|CELL12_CS_03_Pin|CELL12_CS_04_Pin
                          |CELL12_CS_05_Pin|CELL11_CS_10_Pin|CELL11_CS_11_Pin|CELL11_CS_12_Pin
                          |CSU_11_CELLS_Pin, GPIO_PIN_SET);

  /*Configure GPIO pin Output Level */
  HAL_GPIO_WritePin(GPIOI, CELL12_CS_06_Pin|CELL12_CS_08_Pin|CELL12_CS_09_Pin|CELL12_CS_10_Pin, GPIO_PIN_SET);

  /*Configure GPIO pin Output Level */
  HAL_GPIO_WritePin(GPIOC, CELL12_CS_07_Pin|CELL12_TEMP_02_LED_Pin|CELL12_TEMP_03_CS_Pin|SPI3_CS_03_Pin
                          |SPI3_CS_02_Pin, GPIO_PIN_SET);

  /*Configure GPIO pin Output Level */
  HAL_GPIO_WritePin(GPIOF, CELL12_CS_11_Pin|CELL12_CS_12_Pin|CSU_12_CELLS_Pin|CELL12_TEMP_01_CS_Pin
                          |CELL12_TEMP_01_LED_Pin|CELL12_TEMP_02_CS_Pin|CELL11_CS_03_Pin|CELL11_CS_04_Pin
                          |CELL11_CS_05_Pin|CELL11_CS_06_Pin|CELL11_CS_07_Pin, GPIO_PIN_SET);

  /*Configure GPIO pin Output Level */
  HAL_GPIO_WritePin(GPIOF, GPIO_02_Pin|GPIO_03_Pin|GPIO_04_Pin|GPIO_05_Pin
                          |GPIO_06_Pin, GPIO_PIN_RESET);

  /*Configure GPIO pin Output Level */
  HAL_GPIO_WritePin(CELL12_TEMP_03_LED_GPIO_Port, CELL12_TEMP_03_LED_Pin, GPIO_PIN_SET);

  /*Configure GPIO pin Output Level */
  HAL_GPIO_WritePin(USART2_ENABLE_GPIO_Port, USART2_ENABLE_Pin, GPIO_PIN_RESET);

  /*Configure GPIO pin Output Level */
  HAL_GPIO_WritePin(GPIOH, GPIO_14_Pin|GPIO_07_Pin|LED_01_Pin|LED_02_Pin, GPIO_PIN_RESET);

  /*Configure GPIO pin Output Level */
  HAL_GPIO_WritePin(GPIOB, CELL11_CS_01_Pin|CELL11_CS_02_Pin|CELL11_TEMP_01_CS_Pin|CS_Pin, GPIO_PIN_SET);

  /*Configure GPIO pin Output Level */
  HAL_GPIO_WritePin(GPIOG, CELL11_CS_08_Pin|CELL11_CS_09_Pin, GPIO_PIN_SET);

  /*Configure GPIO pin Output Level */
  HAL_GPIO_WritePin(GPIOE, GPIO_09_Pin|GPIO_10_Pin|LED_06_Pin|LED_05_Pin, GPIO_PIN_RESET);

  /*Configure GPIO pin Output Level */
  HAL_GPIO_WritePin(GPIOB, GPIO_11_Pin|GPIO_12_Pin|LED_03_Pin|LED_07_Pin
                          |USART1_ENABLE_Pin, GPIO_PIN_RESET);

  /*Configure GPIO pin Output Level */
  HAL_GPIO_WritePin(GPIOH, CELL11_TEMP_01_LED_Pin|CELL11_TEMP_02_CS_Pin|CELL11_TEMP_02_LED_Pin|CELL11_TEMP_03_CS_Pin
                          |CELL11_TEMP_03_LED_Pin, GPIO_PIN_SET);

  /*Configure GPIO pin Output Level */
  HAL_GPIO_WritePin(CS1_GPIO_Port, CS1_Pin, GPIO_PIN_SET);

  /*Configure GPIO pin Output Level */
  HAL_GPIO_WritePin(GPIOD, USART3_ENABLE_Pin|DISPLAY_CS_Pin|SPI5_CS_02_Pin, GPIO_PIN_RESET);

  /*Configure GPIO pin Output Level */
  HAL_GPIO_WritePin(GPIOG, DISPLAY_IO_1_Pin|DISPLAY_IO_2_Pin|BACKLIGHT_1_Pin|BACKLIGHT_2_Pin
                          |LED_09_Pin|LED_04_Pin|LED_08_Pin, GPIO_PIN_RESET);

  /*Configure GPIO pin Output Level */
  HAL_GPIO_WritePin(USART6_ENABLE_GPIO_Port, USART6_ENABLE_Pin, GPIO_PIN_RESET);

  /*Configure GPIO pin Output Level */
  HAL_GPIO_WritePin(GPIOI, LED_DC_Y_Pin|LED_DC_G_Pin|LED_PC_Y_Pin|LED_PC_G_Pin, GPIO_PIN_RESET);

  /*Configure GPIO pins : CELL12_CS_01_Pin CELL12_CS_02_Pin CELL12_CS_03_Pin CELL12_CS_04_Pin
                           CELL12_CS_05_Pin CELL11_CS_10_Pin CELL11_CS_11_Pin CELL11_CS_12_Pin
                           CSU_11_CELLS_Pin GPIO_09_Pin GPIO_10_Pin LED_06_Pin
                           LED_05_Pin */
  GPIO_InitStruct.Pin = CELL12_CS_01_Pin|CELL12_CS_02_Pin|CELL12_CS_03_Pin|CELL12_CS_04_Pin
                          |CELL12_CS_05_Pin|CELL11_CS_10_Pin|CELL11_CS_11_Pin|CELL11_CS_12_Pin
                          |CSU_11_CELLS_Pin|GPIO_09_Pin|GPIO_10_Pin|LED_06_Pin
                          |LED_05_Pin;
  GPIO_InitStruct.Mode = GPIO_MODE_OUTPUT_PP;
  GPIO_InitStruct.Pull = GPIO_NOPULL;
  GPIO_InitStruct.Speed = GPIO_SPEED_FREQ_LOW;
  HAL_GPIO_Init(GPIOE, &GPIO_InitStruct);

  /*Configure GPIO pins : CELL12_CS_06_Pin CELL12_CS_08_Pin CELL12_CS_09_Pin CELL12_CS_10_Pin
                           LED_DC_Y_Pin LED_DC_G_Pin LED_PC_Y_Pin LED_PC_G_Pin */
  GPIO_InitStruct.Pin = CELL12_CS_06_Pin|CELL12_CS_08_Pin|CELL12_CS_09_Pin|CELL12_CS_10_Pin
                          |LED_DC_Y_Pin|LED_DC_G_Pin|LED_PC_Y_Pin|LED_PC_G_Pin;
  GPIO_InitStruct.Mode = GPIO_MODE_OUTPUT_PP;
  GPIO_InitStruct.Pull = GPIO_NOPULL;
  GPIO_InitStruct.Speed = GPIO_SPEED_FREQ_LOW;
  HAL_GPIO_Init(GPIOI, &GPIO_InitStruct);

  /*Configure GPIO pins : CELL12_CS_07_Pin SPI3_CS_03_Pin SPI3_CS_02_Pin USART6_ENABLE_Pin */
  GPIO_InitStruct.Pin = CELL12_CS_07_Pin|SPI3_CS_03_Pin|SPI3_CS_02_Pin|USART6_ENABLE_Pin;
  GPIO_InitStruct.Mode = GPIO_MODE_OUTPUT_PP;
  GPIO_InitStruct.Pull = GPIO_NOPULL;
  GPIO_InitStruct.Speed = GPIO_SPEED_FREQ_LOW;
  HAL_GPIO_Init(GPIOC, &GPIO_InitStruct);

  /*Configure GPIO pins : CELL12_CS_11_Pin CELL12_CS_12_Pin GPIO_02_Pin GPIO_03_Pin
                           GPIO_04_Pin GPIO_05_Pin GPIO_06_Pin CELL11_CS_03_Pin
                           CELL11_CS_04_Pin CELL11_CS_05_Pin CELL11_CS_06_Pin CELL11_CS_07_Pin */
  GPIO_InitStruct.Pin = CELL12_CS_11_Pin|CELL12_CS_12_Pin|GPIO_02_Pin|GPIO_03_Pin
                          |GPIO_04_Pin|GPIO_05_Pin|GPIO_06_Pin|CELL11_CS_03_Pin
                          |CELL11_CS_04_Pin|CELL11_CS_05_Pin|CELL11_CS_06_Pin|CELL11_CS_07_Pin;
  GPIO_InitStruct.Mode = GPIO_MODE_OUTPUT_PP;
  GPIO_InitStruct.Pull = GPIO_NOPULL;
  GPIO_InitStruct.Speed = GPIO_SPEED_FREQ_LOW;
  HAL_GPIO_Init(GPIOF, &GPIO_InitStruct);

  /*Configure GPIO pin : CSU_12_CELLS_Pin */
  GPIO_InitStruct.Pin = CSU_12_CELLS_Pin;
  GPIO_InitStruct.Mode = GPIO_MODE_OUTPUT_PP;
  GPIO_InitStruct.Pull = GPIO_NOPULL;
  GPIO_InitStruct.Speed = GPIO_SPEED_FREQ_HIGH;
  HAL_GPIO_Init(CSU_12_CELLS_GPIO_Port, &GPIO_InitStruct);

  /*Configure GPIO pins : CELL12_TEMP_01_CS_Pin CELL12_TEMP_02_CS_Pin */
  GPIO_InitStruct.Pin = CELL12_TEMP_01_CS_Pin|CELL12_TEMP_02_CS_Pin;
  GPIO_InitStruct.Mode = GPIO_MODE_OUTPUT_PP;
  GPIO_InitStruct.Pull = GPIO_PULLUP;
  GPIO_InitStruct.Speed = GPIO_SPEED_FREQ_VERY_HIGH;
  HAL_GPIO_Init(GPIOF, &GPIO_InitStruct);

  /*Configure GPIO pin : CELL12_TEMP_01_LED_Pin */
  GPIO_InitStruct.Pin = CELL12_TEMP_01_LED_Pin;
  GPIO_InitStruct.Mode = GPIO_MODE_OUTPUT_PP;
  GPIO_InitStruct.Pull = GPIO_PULLDOWN;
  GPIO_InitStruct.Speed = GPIO_SPEED_FREQ_VERY_HIGH;
  HAL_GPIO_Init(CELL12_TEMP_01_LED_GPIO_Port, &GPIO_InitStruct);

  /*Configure GPIO pin : CELL12_TEMP_02_LED_Pin */
  GPIO_InitStruct.Pin = CELL12_TEMP_02_LED_Pin;
  GPIO_InitStruct.Mode = GPIO_MODE_OUTPUT_PP;
  GPIO_InitStruct.Pull = GPIO_PULLDOWN;
  GPIO_InitStruct.Speed = GPIO_SPEED_FREQ_VERY_HIGH;
  HAL_GPIO_Init(CELL12_TEMP_02_LED_GPIO_Port, &GPIO_InitStruct);

  /*Configure GPIO pin : CELL12_TEMP_03_CS_Pin */
  GPIO_InitStruct.Pin = CELL12_TEMP_03_CS_Pin;
  GPIO_InitStruct.Mode = GPIO_MODE_OUTPUT_PP;
  GPIO_InitStruct.Pull = GPIO_PULLUP;
  GPIO_InitStruct.Speed = GPIO_SPEED_FREQ_VERY_HIGH;
  HAL_GPIO_Init(CELL12_TEMP_03_CS_GPIO_Port, &GPIO_InitStruct);

  /*Configure GPIO pin : CELL12_TEMP_03_LED_Pin */
  GPIO_InitStruct.Pin = CELL12_TEMP_03_LED_Pin;
  GPIO_InitStruct.Mode = GPIO_MODE_OUTPUT_PP;
  GPIO_InitStruct.Pull = GPIO_PULLDOWN;
  GPIO_InitStruct.Speed = GPIO_SPEED_FREQ_VERY_HIGH;
  HAL_GPIO_Init(CELL12_TEMP_03_LED_GPIO_Port, &GPIO_InitStruct);

  /*Configure GPIO pin : USART2_ENABLE_Pin */
  GPIO_InitStruct.Pin = USART2_ENABLE_Pin;
  GPIO_InitStruct.Mode = GPIO_MODE_OUTPUT_PP;
  GPIO_InitStruct.Pull = GPIO_NOPULL;
  GPIO_InitStruct.Speed = GPIO_SPEED_FREQ_HIGH;
  HAL_GPIO_Init(USART2_ENABLE_GPIO_Port, &GPIO_InitStruct);

  /*Configure GPIO pins : GPIO_14_Pin GPIO_07_Pin LED_01_Pin LED_02_Pin */
  GPIO_InitStruct.Pin = GPIO_14_Pin|GPIO_07_Pin|LED_01_Pin|LED_02_Pin;
  GPIO_InitStruct.Mode = GPIO_MODE_OUTPUT_PP;
  GPIO_InitStruct.Pull = GPIO_NOPULL;
  GPIO_InitStruct.Speed = GPIO_SPEED_FREQ_LOW;
  HAL_GPIO_Init(GPIOH, &GPIO_InitStruct);

  /*Configure GPIO pins : CELL11_CS_01_Pin CELL11_CS_02_Pin GPIO_11_Pin GPIO_12_Pin
                           CS_Pin LED_03_Pin LED_07_Pin USART1_ENABLE_Pin */
  GPIO_InitStruct.Pin = CELL11_CS_01_Pin|CELL11_CS_02_Pin|GPIO_11_Pin|GPIO_12_Pin
                          |CS_Pin|LED_03_Pin|LED_07_Pin|USART1_ENABLE_Pin;
  GPIO_InitStruct.Mode = GPIO_MODE_OUTPUT_PP;
  GPIO_InitStruct.Pull = GPIO_NOPULL;
  GPIO_InitStruct.Speed = GPIO_SPEED_FREQ_LOW;
  HAL_GPIO_Init(GPIOB, &GPIO_InitStruct);

  /*Configure GPIO pins : CELL11_CS_08_Pin CELL11_CS_09_Pin DISPLAY_IO_1_Pin DISPLAY_IO_2_Pin
                           BACKLIGHT_1_Pin BACKLIGHT_2_Pin LED_09_Pin LED_04_Pin
                           LED_08_Pin */
  GPIO_InitStruct.Pin = CELL11_CS_08_Pin|CELL11_CS_09_Pin|DISPLAY_IO_1_Pin|DISPLAY_IO_2_Pin
                          |BACKLIGHT_1_Pin|BACKLIGHT_2_Pin|LED_09_Pin|LED_04_Pin
                          |LED_08_Pin;
  GPIO_InitStruct.Mode = GPIO_MODE_OUTPUT_PP;
  GPIO_InitStruct.Pull = GPIO_NOPULL;
  GPIO_InitStruct.Speed = GPIO_SPEED_FREQ_LOW;
  HAL_GPIO_Init(GPIOG, &GPIO_InitStruct);

  /*Configure GPIO pin : CELL11_TEMP_01_CS_Pin */
  GPIO_InitStruct.Pin = CELL11_TEMP_01_CS_Pin;
  GPIO_InitStruct.Mode = GPIO_MODE_OUTPUT_PP;
  GPIO_InitStruct.Pull = GPIO_PULLUP;
  GPIO_InitStruct.Speed = GPIO_SPEED_FREQ_VERY_HIGH;
  HAL_GPIO_Init(CELL11_TEMP_01_CS_GPIO_Port, &GPIO_InitStruct);

  /*Configure GPIO pins : CELL11_TEMP_01_LED_Pin CELL11_TEMP_02_LED_Pin CELL11_TEMP_03_LED_Pin */
  GPIO_InitStruct.Pin = CELL11_TEMP_01_LED_Pin|CELL11_TEMP_02_LED_Pin|CELL11_TEMP_03_LED_Pin;
  GPIO_InitStruct.Mode = GPIO_MODE_OUTPUT_PP;
  GPIO_InitStruct.Pull = GPIO_PULLDOWN;
  GPIO_InitStruct.Speed = GPIO_SPEED_FREQ_VERY_HIGH;
  HAL_GPIO_Init(GPIOH, &GPIO_InitStruct);

  /*Configure GPIO pins : CELL11_TEMP_02_CS_Pin CELL11_TEMP_03_CS_Pin */
  GPIO_InitStruct.Pin = CELL11_TEMP_02_CS_Pin|CELL11_TEMP_03_CS_Pin;
  GPIO_InitStruct.Mode = GPIO_MODE_OUTPUT_PP;
  GPIO_InitStruct.Pull = GPIO_PULLUP;
  GPIO_InitStruct.Speed = GPIO_SPEED_FREQ_VERY_HIGH;
  HAL_GPIO_Init(GPIOH, &GPIO_InitStruct);

  /*Configure GPIO pins : CS1_Pin USART3_ENABLE_Pin DISPLAY_CS_Pin SPI5_CS_02_Pin */
  GPIO_InitStruct.Pin = CS1_Pin|USART3_ENABLE_Pin|DISPLAY_CS_Pin|SPI5_CS_02_Pin;
  GPIO_InitStruct.Mode = GPIO_MODE_OUTPUT_PP;
  GPIO_InitStruct.Pull = GPIO_NOPULL;
  GPIO_InitStruct.Speed = GPIO_SPEED_FREQ_LOW;
  HAL_GPIO_Init(GPIOD, &GPIO_InitStruct);

  /*Configure GPIO pins : PUSH_BUTTON_01_Pin PUSH_BUTTON_02_Pin PUSH_BUTTON_03_Pin PUSH_BUTTON_04_Pin */
  GPIO_InitStruct.Pin = PUSH_BUTTON_01_Pin|PUSH_BUTTON_02_Pin|PUSH_BUTTON_03_Pin|PUSH_BUTTON_04_Pin;
  GPIO_InitStruct.Mode = GPIO_MODE_IT_RISING;
  GPIO_InitStruct.Pull = GPIO_NOPULL;
  HAL_GPIO_Init(GPIOD, &GPIO_InitStruct);

  /*Configure GPIO pin : CD_Pin */
  GPIO_InitStruct.Pin = CD_Pin;
  GPIO_InitStruct.Mode = GPIO_MODE_INPUT;
  GPIO_InitStruct.Pull = GPIO_PULLUP;
  HAL_GPIO_Init(CD_GPIO_Port, &GPIO_InitStruct);

  /*Configure GPIO pins : DIP_SWITCH_01_Pin DIP_SWITCH_02_Pin DIP_SWITCH_03_Pin DIP_SWITCH_04_Pin */
  GPIO_InitStruct.Pin = DIP_SWITCH_01_Pin|DIP_SWITCH_02_Pin|DIP_SWITCH_03_Pin|DIP_SWITCH_04_Pin;
  GPIO_InitStruct.Mode = GPIO_MODE_INPUT;
  GPIO_InitStruct.Pull = GPIO_NOPULL;
  HAL_GPIO_Init(GPIOD, &GPIO_InitStruct);

  /*Configure GPIO pins : DIP_SWITCH_MODE_01_Pin DIP_SWITCH_MODE_02_Pin DIP_SWITCH_MODE_03_Pin DIP_SWITCH_MODE_04_Pin */
  GPIO_InitStruct.Pin = DIP_SWITCH_MODE_01_Pin|DIP_SWITCH_MODE_02_Pin|DIP_SWITCH_MODE_03_Pin|DIP_SWITCH_MODE_04_Pin;
  GPIO_InitStruct.Mode = GPIO_MODE_INPUT;
  GPIO_InitStruct.Pull = GPIO_NOPULL;
  HAL_GPIO_Init(GPIOG, &GPIO_InitStruct);

  /* EXTI interrupt init*/
  HAL_NVIC_SetPriority(EXTI15_10_IRQn, 0, 0);
  HAL_NVIC_EnableIRQ(EXTI15_10_IRQn);

}

/* USER CODE BEGIN 4 */

//void init_ina229_devices(void) {
//    ina229_devices[0] = INA229_0;
//    ina229_devices[1] = INA229_1;
//    ina229_devices[2] = INA229_2;
//    ina229_devices[3] = INA229_3;
//    ina229_devices[4] = INA229_4;
//    ina229_devices[5] = INA229_5;
//    ina229_devices[6] = INA229_6;
//    ina229_devices[7] = INA229_7;
//    ina229_devices[8] = INA229_8;
//    ina229_devices[9] = INA229_9;
//    ina229_devices[10] = INA229_10;
//    ina229_devices[11] = INA229_11;
//    ina229_devices[12] = INA229_12;
//    ina229_devices[13] = INA229_13;
//    ina229_devices[14] = INA229_14;
//    ina229_devices[15] = INA229_15;
//    ina229_devices[16] = INA229_16;
//    ina229_devices[17] = INA229_17;
//    ina229_devices[18] = INA229_18;
//    ina229_devices[19] = INA229_19;
//    ina229_devices[20] = INA229_20;
//    ina229_devices[21] = INA229_21;
//    ina229_devices[22] = INA229_22;
//    ina229_devices[23] = INA229_23;
//    ina229_devices[24] = INA229_24;
//    ina229_devices[25] = INA229_25;
//}

void Scan_I2C_Bus(void)
{

      /* Declare the address variable */

    /* Iterate over the possible 7-bit I²C addresses (1 to 127) */
    for (address = 1U; address < 128U; address++)
    {
        /* Check if a device is ready at this address
         * The address is left-shifted by 1 as HAL_I2C_IsDeviceReady expects the 7-bit address in the upper bits.
         */
        result = HAL_I2C_IsDeviceReady(&hi2c2, (address << 1), 1U, 10U);

        if (result == HAL_OK)
        {
            /* Display the detected address (your Display_Address function should handle this)
             * For example, this could light up LEDs or update an LCD.
             */
            Display_Address(address);
            HAL_Delay(1000U);  /* Display the address for 1 second */
        }
    }
}

// Helper macros to make the table more readable
#define I2C2_BUS 2
#define I2C3_BUS 3

//// Define the configurations table
//static const Cell_Config cell_configs[] = {
//		// First GPIO Expander (ID_01) - Cells 1-3
//
//		// FOR THE FIRST 12 CELLS
//    // Cell ID, INA idx, GPIO port,  CS pin,           LED pin
//    { 0,          0,       GPIOE,     CELL12_CS_01_Pin, CELL_01_LED_01},
//    { 1,          1,       GPIOE,     CELL12_CS_02_Pin, CELL_02_LED_01},
//    { 2,          2,       GPIOE,     CELL12_CS_03_Pin, CELL_03_LED_01},
//
//	// Second GPIO Expander (ID_02) - Cells 4-6
//    { 3,          3,       GPIOE,     CELL12_CS_04_Pin, CELL_01_LED_01},
//    { 4,          4,       GPIOE,     CELL12_CS_05_Pin, CELL_02_LED_01},
//    { 5,          5,       GPIOI,     CELL12_CS_06_Pin, CELL_03_LED_01},
//	// Third GPIO Expander (ID_03) - Cells 7-9
//    { 6,          6,       GPIOC,     CELL12_CS_07_Pin, CELL_01_LED_01},
//    { 7,          7,       GPIOI,     CELL12_CS_08_Pin, CELL_02_LED_01},
//    { 8,          8,       GPIOI,     CELL12_CS_09_Pin, CELL_03_LED_01},
//
//	// Fourth GPIO Expander (ID_04) - Cells 10-12
//    { 9,          9,       GPIOI,     CELL12_CS_10_Pin, CELL_01_LED_01},
//    {10,         10,       GPIOF,     CELL12_CS_11_Pin, CELL_02_LED_01},
//    {11,         11,       GPIOF,     CELL12_CS_12_Pin, CELL_03_LED_01},
//
//	// FOR THE SECOND 12 CELLS
//    // Cell ID, I2C bus, INA idx, GPIO port,  CS pin,           LED pin
//    {12,         13,       GPIOB,     CELL11_CS_01_Pin, CELL_01_LED_01},
//    {13,         14,       GPIOB,     CELL11_CS_02_Pin, CELL_02_LED_01},
//    {14,         15,       GPIOF,     CELL11_CS_03_Pin, CELL_03_LED_01},
//
//	// Second GPIO Expander (ID_02) - Cells 4-6
//    {15,         16,       GPIOF,     CELL11_CS_04_Pin, CELL_01_LED_01},
//    {16,         17,       GPIOF,     CELL11_CS_05_Pin, CELL_02_LED_01},
//    {17,         18,       GPIOF,     CELL11_CS_06_Pin, CELL_03_LED_01},
//	// Third GPIO Expander (ID_03) - Cells 7-9
//    {18,         19,       GPIOF,     CELL11_CS_07_Pin, CELL_01_LED_01},
//    {19,         20,       GPIOG,     CELL11_CS_08_Pin, CELL_02_LED_01},
//    {20,         21,       GPIOG,     CELL11_CS_09_Pin, CELL_03_LED_01},
//
//	// Fourth GPIO Expander (ID_04) - Cells 10-12
//    {21,         22,       GPIOE,     CELL11_CS_10_Pin, CELL_01_LED_01},
//    {22,         23,       GPIOE,     CELL11_CS_11_Pin, CELL_02_LED_01},
//    {23,         24,       GPIOE,     CELL11_CS_12_Pin, CELL_03_LED_01},
//
//	//12 cell CSU voltage and current reading
//	{24,         12,       GPIOF,     CSU_12_CELLS_Pin, CELL_01_LED_01},
//
//	//11 cell CSU voltage and current reading
//	{25,         25,       GPIOE,     CSU_11_CELLS_Pin, CELL_03_LED_01}
//
//
//};

// Helper function to get INA handle from index
static INA229_Handle get_ina_handle(uint8_t index) {
    return INA229_0 + index;  // Assuming INA handles are sequential
}

//void Voltage_Sequence_Automatic(void)
//{
//
//    const float test_voltages[] = {2.0f, 2.5f, 2.8f, 3.3f, 3.4f, 3.6f, 4.0f, 4.2f};
//    const int num_voltages = sizeof(test_voltages) / sizeof(test_voltages[0]);
//    const int num_cells = sizeof(cell_configs) / sizeof(cell_configs[0]);
//
//    for(int v = 0; v < num_voltages; v++) {
//        for(int c = 0; c < num_cells; c++) {
//        	Set_voltage_and_measure(&cell_configs[c], test_voltages[v]);
//
//        	cell_voltage_read();
//
//            HAL_Delay(10);  // Delay between cells
//        }
//        HAL_Delay(10);  // Delay between voltage levels
//    }
//
//
//
//
//
//
//}

//void Set_voltage_and_measure(const Cell_Config* cell, float voltage)
//
//{
//    // Get the actual handles from the configuration
//    INA229_Handle ina = get_ina_handle(cell->ina_index);
//
//    // Only set voltage and control LED for cells 0-11 (skip CSU cells 12 and 13) COZ this is for the slave board reading
//    if (cell->cell_id != 24 && cell->cell_id != 25)
//
//    {
//
//    // Set voltage for the cell
//    Set_Output_Voltage(cell->cell_id, voltage);
//
//    // Turn on LED
//
//    Set_LED_status(cell->cell_id, OFF);
//
//    }
//    HAL_Delay(10);
//    // Read voltage and temperature
//    HAL_GPIO_WritePin(cell->gpio, cell->cs_pin, GPIO_PIN_RESET);
//    HAL_Delay(1);
//    INA229_Readings[cell->ina_index].voltage_V = INA229_getVBUS_V(ina);
//    HAL_Delay(1);
//    HAL_GPIO_WritePin(cell->gpio, cell->cs_pin, GPIO_PIN_SET);
//
////    HAL_Delay(10);
//
////    HAL_GPIO_WritePin(cell->gpio, cell->cs_pin, GPIO_PIN_RESET);
////    HAL_Delay(1);
////    INA229_Readings[cell->ina_index].temperature_C = INA229_getDIETEMP_C(ina);
////    HAL_Delay(1);
////    HAL_GPIO_WritePin(cell->gpio, cell->cs_pin, GPIO_PIN_SET);
//
//    // Turn off LED
//    HAL_Delay(10);
//
//    // Only turn off LED for cells 0-11 (skip CSU cells 12 and 13)
//    if (cell->cell_id != 24 && cell->cell_id != 25)
//
//    {
//
//    Set_LED_status(cell->cell_id, ON);
//
//    }
//}

void HAL_UARTEx_RxEventCallback(UART_HandleTypeDef *huart, uint16_t Size)
{

	/*

	if (RxData_modbus_01[0] == SLAVE_ID)
	{
		switch (RxData_modbus_01[1]){
		case 0x03:
			readHoldingRegs();
			break;
		case 0x04:
			readInputRegs();
			break;
		case 0x01:
			readCoils();
			break;
		case 0x02:
			readInputs();
			break;
		case 0x06:
			writeSingleReg();
			break;
		case 0x10:
			writeHoldingRegs();
			break;
		case 0x05:
			writeSingleCoil();
			break;
		case 0x0F:
			writeMultiCoils();
			break;
		default:
			modbusException(ILLEGAL_FUNCTION);
			break;
		}
	}
    */

	HAL_UARTEx_ReceiveToIdle_IT(&huart1, RxData_modbus_01, sizeof(RxData_modbus_01));

	HAL_UARTEx_ReceiveToIdle_IT(&huart2, RxData_modbus_02, sizeof(RxData_modbus_02));

	HAL_UARTEx_ReceiveToIdle_IT(&huart3, RxData_modbus_03, sizeof(RxData_modbus_03));

	HAL_UARTEx_ReceiveToIdle_IT(&huart6, RxData_modbus_04, sizeof(RxData_modbus_04));

	modebus_rx_flag = 1 ;

	  flag_1 = 2 ;

	  HAL_TIM_Base_Start_IT(&htim1);

//    tester_setup();

//	modebus_rx_flag = 0;

//	HAL_UART_RxCpltCallback
}

void HAL_TIM_PeriodElapsedCallback(TIM_HandleTypeDef *htim){
	timeout_flag = 1;
	testcount++;
}

void HAL_GPIO_EXTI_Callback(uint16_t GPIO_Pin)
{
    UNUSED(GPIO_Pin);
    Push_ButtonHandler(GPIO_Pin);
}

/* USER CODE END 4 */

void Error_Handler(void)
{
  __disable_irq();
  while (1)
  {
  }
}
